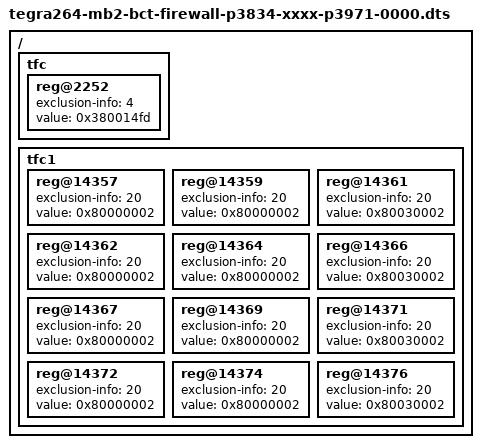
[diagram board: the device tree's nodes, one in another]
/*
 * SPDX-FileCopyrightText: Copyright (c) 2024-2025, NVIDIA CORPORATION & AFFILIATES. All rights reserved.
 * SPDX-License-Identifier: BSD-3-Clause
 *
 * Redistribution and use in source and binary forms, with or without
 * modification, are permitted provided that the following conditions are met:
 *
 * 1. Redistributions of source code must retain the above copyright notice, this
 * list of conditions and the following disclaimer.
 *
 * 2. Redistributions in binary form must reproduce the above copyright notice,
 * this list of conditions and the following disclaimer in the documentation
 * and/or other materials provided with the distribution.
 *
 * 3. Neither the name of the copyright holder nor the names of its
 * contributors may be used to endorse or promote products derived from
 * this software without specific prior written permission.
 *
 * THIS SOFTWARE IS PROVIDED BY THE COPYRIGHT HOLDERS AND CONTRIBUTORS "AS IS"
 * AND ANY EXPRESS OR IMPLIED WARRANTIES, INCLUDING, BUT NOT LIMITED TO, THE
 * IMPLIED WARRANTIES OF MERCHANTABILITY AND FITNESS FOR A PARTICULAR PURPOSE ARE
 * DISCLAIMED. IN NO EVENT SHALL THE COPYRIGHT HOLDER OR CONTRIBUTORS BE LIABLE
 * FOR ANY DIRECT, INDIRECT, INCIDENTAL, SPECIAL, EXEMPLARY, OR CONSEQUENTIAL
 * DAMAGES (INCLUDING, BUT NOT LIMITED TO, PROCUREMENT OF SUBSTITUTE GOODS OR
 * SERVICES; LOSS OF USE, DATA, OR PROFITS; OR BUSINESS INTERRUPTION) HOWEVER
 * CAUSED AND ON ANY THEORY OF LIABILITY, WHETHER IN CONTRACT, STRICT LIABILITY,
 * OR TORT (INCLUDING NEGLIGENCE OR OTHERWISE) ARISING IN ANY WAY OUT OF THE USE
 * OF THIS SOFTWARE, EVEN IF ADVISED OF THE POSSIBILITY OF SUCH DAMAGE.
 */
/*
# CFG Version 1.0
# This File contains the configuration of multiple rails.
*/
/dts-v1/;

#include "tegra264-firewall-config-base.dtsi"

/ {
    tfc {
        reg@2252 { /* GPIO_CTL_UCF, GPIO_F_SCR_04_0 */
            exclusion-info = <4>;
            value = <0x380014fd>;
        };
    };

    tfc1 {
        reg@14357 { /* FSI_FABRIC, FSI_CONTROL_FIREWALL_FSI_CAN0_BLF, READ_CTL_0 */
            exclusion-info = <20>;
            value = <0x80000002>;
        };

        reg@14359 { /* FSI_FABRIC, FSI_CONTROL_FIREWALL_FSI_CAN0_BLF, WRITE_CTL_0 */
            exclusion-info = <20>;
            value = <0x80000002>;
        };

        reg@14361 { /* FSI_FABRIC, FSI_CONTROL_FIREWALL_FSI_CAN0_BLF, CTL_SETTING */
            exclusion-info = <20>;
            value = <0x80030002>;
        };

        reg@14362 { /* FSI_FABRIC, FSI_CONTROL_FIREWALL_FSI_CAN1_BLF, READ_CTL_0 */
            exclusion-info = <20>;
            value = <0x80000002>;
        };

        reg@14364 { /* FSI_FABRIC, FSI_CONTROL_FIREWALL_FSI_CAN1_BLF, WRITE_CTL_0 */
            exclusion-info = <20>;
            value = <0x80000002>;
        };

        reg@14366 { /* FSI_FABRIC, FSI_CONTROL_FIREWALL_FSI_CAN1_BLF, CTL_SETTING */
            exclusion-info = <20>;
            value = <0x80030002>;
        };

        reg@14367 { /* FSI_FABRIC, FSI_CONTROL_FIREWALL_FSI_CAN2_BLF, READ_CTL_0 */
            exclusion-info = <20>;
            value = <0x80000002>;
        };

        reg@14369 { /* FSI_FABRIC, FSI_CONTROL_FIREWALL_FSI_CAN2_BLF, WRITE_CTL_0 */
            exclusion-info = <20>;
            value = <0x80000002>;
        };

        reg@14371 { /* FSI_FABRIC, FSI_CONTROL_FIREWALL_FSI_CAN2_BLF, CTL_SETTING */
            exclusion-info = <20>;
            value = <0x80030002>;
        };

        reg@14372 { /* FSI_FABRIC, FSI_CONTROL_FIREWALL_FSI_CAN3_BLF, READ_CTL_0 */
            exclusion-info = <20>;
            value = <0x80000002>;
        };

        reg@14374 { /* FSI_FABRIC, FSI_CONTROL_FIREWALL_FSI_CAN3_BLF, WRITE_CTL_0 */
            exclusion-info = <20>;
            value = <0x80000002>;
        };

        reg@14376 { /* FSI_FABRIC, FSI_CONTROL_FIREWALL_FSI_CAN3_BLF, CTL_SETTING */
            exclusion-info = <20>;
            value = <0x80030002>;
        };
    };
};

